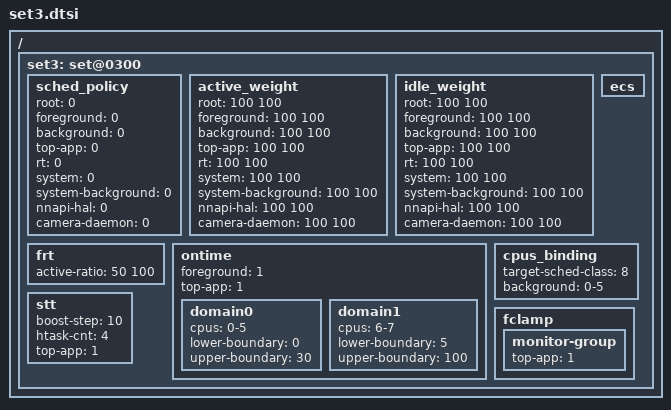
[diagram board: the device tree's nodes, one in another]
/ {
	/* game mode - default */
	set3: set@0300{
		sched_policy {
			root = <0>;
			foreground = <0>;
			background = <0>;
			top-app = <0>;
			rt = <0>;
			system = <0>;
			system-background = <0>;
			nnapi-hal = <0>;
			camera-daemon = <0>;
		};

		active_weight {
			root = <100 100>;
			foreground = <100 100>;
			background = <100 100>;
			top-app = <100 100>;
			rt = <100 100>;
			system = <100 100>;
			system-background = <100 100>;
			nnapi-hal = <100 100>;
			camera-daemon = <100 100>;
		};

		idle_weight {
			root = <100 100>;
			foreground = <100 100>;
			background = <100 100>;
			top-app = <100 100>;
			rt = <100 100>;
			system = <100 100>;
			system-background = <100 100>;
			nnapi-hal = <100 100>;
			camera-daemon = <100 100>;
		};

		frt {	   			/* LIT BIG */
			active-ratio 		= < 50 100>;
		};

		/* Ontime Migration */
		ontime {
			foreground	= <1>;
			top-app		= <1>;

			domain0 {
				cpus = "0-5";
				lower-boundary = <0>;
				upper-boundary = <30>;
			};
			domain1 {
				cpus = "6-7";
				lower-boundary = <5>;
				upper-boundary = <100>;
			};
		};

		ecs { };

		/* cpus_binding applied to core selection */
		cpus_binding {
			target-sched-class = <8>;	/* fair */

			background	= "0-5";
		};

		stt {
			boost-step = <10>;
			htask-cnt = <4>;
			top-app = <1>;
		};

		fclamp {
			monitor-group {
				top-app         = <1>;
			};
		};
	};
};
